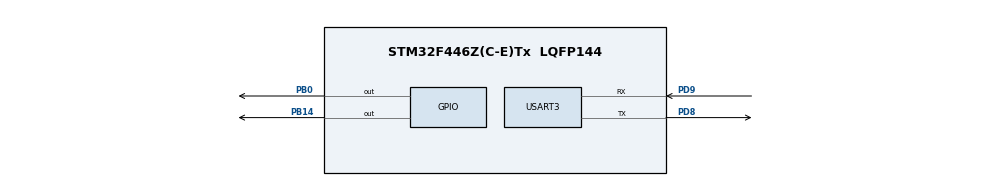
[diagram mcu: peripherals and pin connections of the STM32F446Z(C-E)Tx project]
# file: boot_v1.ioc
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Mcu.Family=STM32F4
Mcu.Name=STM32F446Z(C-E)Tx
Mcu.Package=LQFP144
NVIC.PriorityGroup=NVIC_PRIORITYGROUP_4
PB0.Signal=GPIO_Output
PB14.Signal=GPIO_Output
PD8.Mode=Asynchronous
PD8.Signal=USART3_TX
PD9.Mode=Asynchronous
PD9.Signal=USART3_RX
ProjectManager.HeapSize=0x200
ProjectManager.StackSize=0x400
ProjectManager.TargetToolchain=STM32CubeIDE
RCC.CortexFreq_Value=16000000
RCC.USBFreq_Value=96000000
RCC.VCOOutputFreq_Value=192000000
USART3.VirtualMode=VM_ASYNC
board=custom

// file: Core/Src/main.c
/* USER CODE BEGIN Header */
/**
  ******************************************************************************
  * @file           : main.c
  * @brief          : Main program body
  ******************************************************************************
  * @attention
  *
  * Copyright (c) 2026 STMicroelectronics.
  * All rights reserved.
  *
  * This software is licensed under terms that can be found in the LICENSE file
  * in the root directory of this software component.
  * If no LICENSE file comes with this software, it is provided AS-IS.
  *
  ******************************************************************************
  */
/* USER CODE END Header */
#include "main.h"
#include "app_jump.h"

CRC_HandleTypeDef hcrc;

UART_HandleTypeDef huart3;

void SystemClock_Config(void);
static void MX_GPIO_Init(void);
static void MX_USART3_UART_Init(void);
static void MX_CRC_Init(void);

int main(void)
{

  /* MCU Configuration--------------------------------------------------------*/

  /* Reset of all peripherals, Initializes the Flash interface and the Systick. */
  HAL_Init();

  /* Configure the system clock */
  SystemClock_Config();

  /* Initialize all configured peripherals */
  MX_GPIO_Init();
  MX_USART3_UART_Init();
  MX_CRC_Init();
  /* USER CODE BEGIN 2 */
  HAL_UART_Transmit(&huart3,(uint8_t*)"Inside the bootloader",21,100);

  if(wait_for_trigger())
  {
      HAL_UART_Transmit(&huart3, (uint8_t*)"Entering update mode\r\n", 22, 100);
      // OTA update function will go here
  }
  else
  {
      if(is_app_valid() && verify_app_crc())
      {
          HAL_UART_Transmit(&huart3, (uint8_t*)"App valid, jumping...\r\n", 23, 100);
          bootloader__jump_to_app();
      }
      else
      {
          HAL_UART_Transmit(&huart3, (uint8_t*)"App invalid, staying in bootloader\r\n", 36, 100);
      }
  }
  /* USER CODE END 2 */

  /* Infinite loop */
  while (1)
  {

    /* USER CODE BEGIN 3 */
	  HAL_GPIO_TogglePin(GPIOB,GPIO_PIN_0);
	  HAL_Delay(500);
  }
  /* USER CODE END 3 */
}

void SystemClock_Config(void)
{
  RCC_OscInitTypeDef RCC_OscInitStruct = {0};
  RCC_ClkInitTypeDef RCC_ClkInitStruct = {0};

  /** Configure the main internal regulator output voltage
  */
  __HAL_RCC_PWR_CLK_ENABLE();
  __HAL_PWR_VOLTAGESCALING_CONFIG(PWR_REGULATOR_VOLTAGE_SCALE3);

  /** Initializes the RCC Oscillators according to the specified parameters
  * in the RCC_OscInitTypeDef structure.
  */
  RCC_OscInitStruct.OscillatorType = RCC_OSCILLATORTYPE_HSI;
  RCC_OscInitStruct.HSIState = RCC_HSI_ON;
  RCC_OscInitStruct.HSICalibrationValue = RCC_HSICALIBRATION_DEFAULT;
  RCC_OscInitStruct.PLL.PLLState = RCC_PLL_NONE;
  if (HAL_RCC_OscConfig(&RCC_OscInitStruct) != HAL_OK)
  {
    Error_Handler();
  }

  /** Initializes the CPU, AHB and APB buses clocks
  */
  RCC_ClkInitStruct.ClockType = RCC_CLOCKTYPE_HCLK|RCC_CLOCKTYPE_SYSCLK
                              |RCC_CLOCKTYPE_PCLK1|RCC_CLOCKTYPE_PCLK2;
  RCC_ClkInitStruct.SYSCLKSource = RCC_SYSCLKSOURCE_HSI;
  RCC_ClkInitStruct.AHBCLKDivider = RCC_SYSCLK_DIV1;
  RCC_ClkInitStruct.APB1CLKDivider = RCC_HCLK_DIV1;
  RCC_ClkInitStruct.APB2CLKDivider = RCC_HCLK_DIV1;

  if (HAL_RCC_ClockConfig(&RCC_ClkInitStruct, FLASH_LATENCY_0) != HAL_OK)
  {
    Error_Handler();
  }
}

static void MX_CRC_Init(void)
{

  hcrc.Instance = CRC;
  if (HAL_CRC_Init(&hcrc) != HAL_OK)
  {
    Error_Handler();
  }

}

static void MX_USART3_UART_Init(void)
{

  huart3.Instance = USART3;
  huart3.Init.BaudRate = 115200;
  huart3.Init.WordLength = UART_WORDLENGTH_8B;
  huart3.Init.StopBits = UART_STOPBITS_1;
  huart3.Init.Parity = UART_PARITY_NONE;
  huart3.Init.Mode = UART_MODE_TX_RX;
  huart3.Init.HwFlowCtl = UART_HWCONTROL_NONE;
  huart3.Init.OverSampling = UART_OVERSAMPLING_16;
  if (HAL_UART_Init(&huart3) != HAL_OK)
  {
    Error_Handler();
  }

}

static void MX_GPIO_Init(void)
{
  GPIO_InitTypeDef GPIO_InitStruct = {0};

  /* GPIO Ports Clock Enable */
  __HAL_RCC_GPIOB_CLK_ENABLE();
  __HAL_RCC_GPIOD_CLK_ENABLE();

  /*Configure GPIO pin Output Level */
  HAL_GPIO_WritePin(GPIOB, GPIO_PIN_0|GPIO_PIN_14, GPIO_PIN_RESET);

  /*Configure GPIO pins : PB0 PB14 */
  GPIO_InitStruct.Pin = GPIO_PIN_0|GPIO_PIN_14;
  GPIO_InitStruct.Mode = GPIO_MODE_OUTPUT_PP;
  GPIO_InitStruct.Pull = GPIO_NOPULL;
  GPIO_InitStruct.Speed = GPIO_SPEED_FREQ_LOW;
  HAL_GPIO_Init(GPIOB, &GPIO_InitStruct);

}

void Error_Handler(void)
{
  __disable_irq();
  while (1)
  {
  }
}
